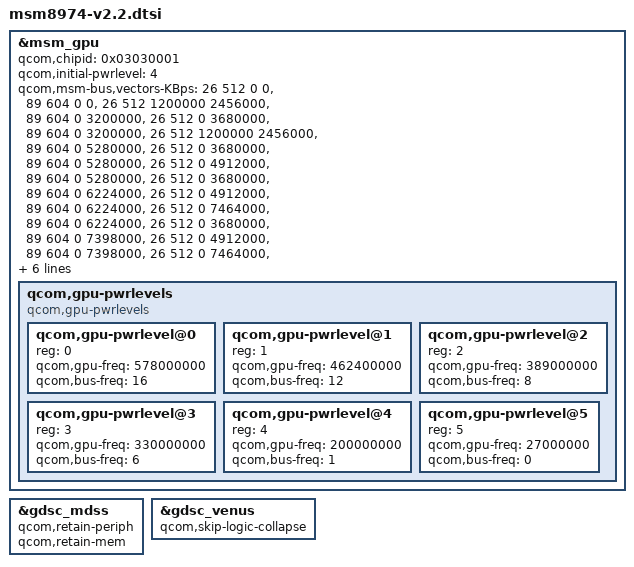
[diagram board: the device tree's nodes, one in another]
/* Copyright (c) 2013-2016, The Linux Foundation. All rights reserved.
 *
 * This program is free software; you can redistribute it and/or modify
 * it under the terms of the GNU General Public License version 2 and
 * only version 2 as published by the Free Software Foundation.
 *
 * This program is distributed in the hope that it will be useful,
 * but WITHOUT ANY WARRANTY; without even the implied warranty of
 * MERCHANTABILITY or FITNESS FOR A PARTICULAR PURPOSE.  See the
 * GNU General Public License for more details.
 *
 * As a general rule, only version-specific property overrides should be placed
 * inside this file. However, device definitions should be placed inside the
 * msm8974.dtsi file.
 */

/include/ "msm8974-v2.dtsi"

/* GPU overrides */
&msm_gpu {
	/* Updated chip ID */
	qcom,chipid = <0x03030001>;

	qcom,initial-pwrlevel = <4>;

	/* Updated bus bandwidth requirements */
	qcom,msm-bus,vectors-KBps =
		/* Off */
		<26 512 0 0>, <89 604 0 0>,
		/* SVS */
		<26 512 1200000 2456000>, <89 604 0 3200000>,
		/* low Nominal / SVS */
		<26 512 0 3680000>, <89 604 0 3200000>,
		/* SVS / low Nominal */
		<26 512 1200000 2456000>, <89 604 0 5280000>,
		/* low Nominal / low Nominal */
		<26 512 0 3680000>, <89 604 0 5280000>,
		/* Nominal / low Nominal */
		<26 512 0 4912000>, <89 604 0 5280000>,
		/* low Nominal / Nominal */
		<26 512 0 3680000>, <89 604 0 6224000>,
		/* Nominal / Nominal */
		<26 512 0 4912000>, <89 604 0 6224000>,
		/* Turbo / Nominal */
		<26 512 0 7464000>, <89 604 0 6224000>,
		/* low Nominal / low Turbo */
		<26 512 0 3680000>, <89 604 0 7398000>,
		/* Nominal / low Turbo */
		<26 512 0 4912000>, <89 604 0 7398000>,
		/* Turbo / low Turbo */
		<26 512 0 7464000>, <89 604 0 7398000>,
		/* Nominal / Turbo */
		<26 512 0 4912000>, <89 604 0 9248000>,
		/* Turbo / Turbo */
		<26 512 0 7464000>, <89 604 0 9248000>,
		/* Aux Turbo / low Turbo */
		<26 512 0 8528000>, <89 604 0 9248000>,
		/* Aux Nominal / Turbo */
		<26 512 0 6400000>, <89 604 0 10192000>,
		/* Aux Turbo / Turbo */
		<26 512 0 8528000>, <89 604 0 10192000>;

	qcom,gpu-pwrlevels {
		#address-cells = <1>;
		#size-cells = <0>;

		compatible = "qcom,gpu-pwrlevels";

		qcom,gpu-pwrlevel@0 {
			reg = <0>;
			qcom,gpu-freq = <578000000>;
			qcom,bus-freq = <16>;
		};

		qcom,gpu-pwrlevel@1 {
			reg = <1>;
			qcom,gpu-freq = <462400000>;
			qcom,bus-freq = <12>;
		};

		qcom,gpu-pwrlevel@2 {
			reg = <2>;
			qcom,gpu-freq = <389000000>;
			qcom,bus-freq = <8>;
		};

		qcom,gpu-pwrlevel@3 {
			reg = <3>;
			qcom,gpu-freq = <330000000>;
			qcom,bus-freq = <6>;
		};

		qcom,gpu-pwrlevel@4 {
			reg = <4>;
			qcom,gpu-freq = <200000000>;
			qcom,bus-freq = <1>;
		};

		qcom,gpu-pwrlevel@5 {
			reg = <5>;
			qcom,gpu-freq = <27000000>;
			qcom,bus-freq = <0>;
		};
	};
};

&gdsc_mdss {
	qcom,retain-periph;
	qcom,retain-mem;
};

&gdsc_venus {
	qcom,skip-logic-collapse;
};
